VERSION ""

NS_ :

BS_:

BU_: XXX

BO_ 85 CID_RHFDFQ: 8 XXX
 SG_ sig_znnjpg : 40|1@1+ (1,0) [0|1] "" XXX
 SG_ sig_tseiik : 56|8@1+ (1,0) [0|255] "" XXX

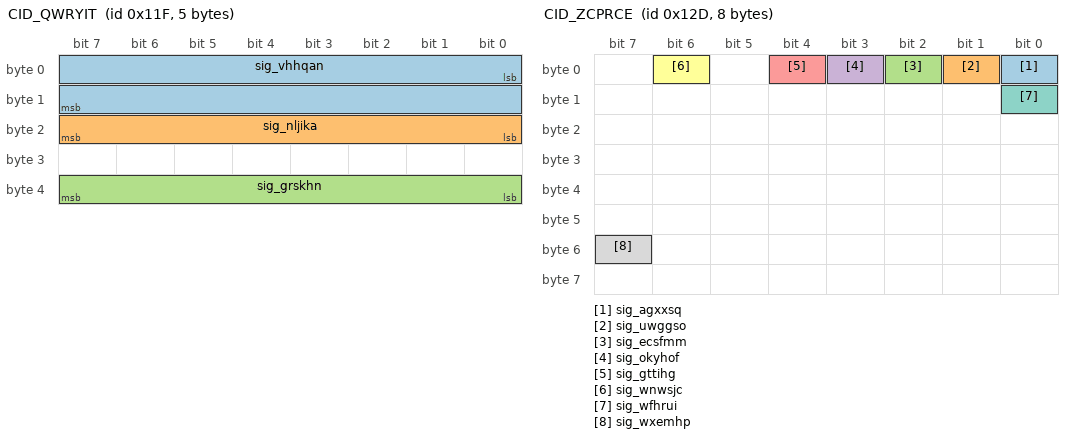
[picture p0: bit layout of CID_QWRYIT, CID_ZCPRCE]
BO_ 287 CID_QWRYIT: 5 XXX
 SG_ sig_vhhqan : 0|16@1- (0.1,0) [-450|450] "" XXX
 SG_ sig_nljika : 16|8@1+ (4,0) [0|1020] "" XXX
 SG_ sig_grskhn : 32|8@1+ (1,0) [0|255] "" XXX

BO_ 289 CID_XDWTUO: 8 XXX
 SG_ sig_wvsqzv : 0|12@1+ (1,0) [0|255] "" XXX

BO_ 301 CID_ZCPRCE: 8 XXX
 SG_ sig_agxxsq : 0|1@0+ (1,0) [0|1] "" XXX
 SG_ sig_uwggso : 1|1@0+ (1,0) [0|1] "" XXX
 SG_ sig_ecsfmm : 2|1@0+ (1,0) [0|1] "" XXX
 SG_ sig_okyhof : 3|1@0+ (1,0) [0|1] "" XXX
 SG_ sig_gttihg : 4|1@0+ (1,0) [0|1] "" XXX
 SG_ sig_wnwsjc : 6|1@0+ (1,0) [0|1] "" XXX
 SG_ sig_wfhrui : 8|1@0+ (1,0) [0|1] "" XXX
 SG_ sig_wxemhp : 55|1@0+ (1,0) [0|1] "" XXX

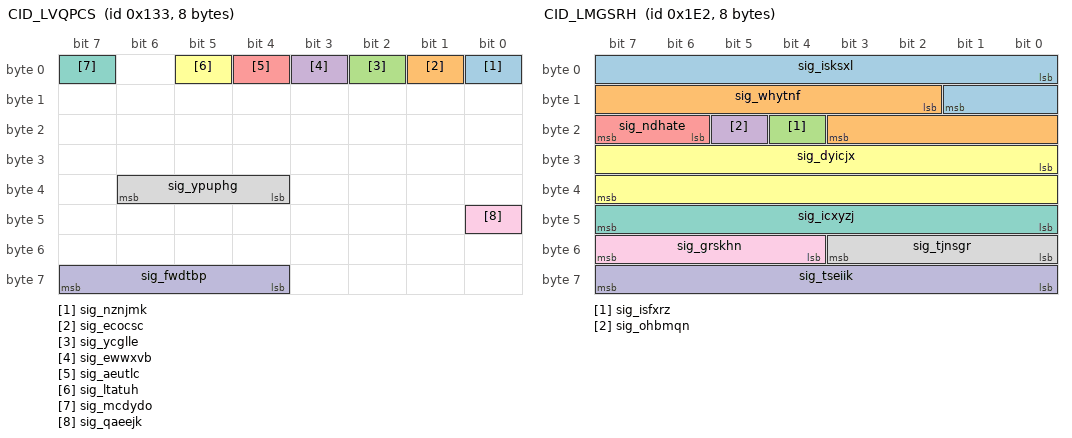
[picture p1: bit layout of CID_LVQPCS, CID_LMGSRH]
BO_ 307 CID_LVQPCS: 8 XXX
 SG_ sig_nznjmk : 0|1@0+ (1,0) [0|1] "" XXX
 SG_ sig_ecocsc : 1|1@1+ (1,0) [0|1] "" XXX
 SG_ sig_ycglle : 2|1@1+ (1,0) [0|1] "" XXX
 SG_ sig_ewwxvb : 3|1@1+ (1,0) [0|1] "" XXX
 SG_ sig_aeutlc : 4|1@0+ (1,0) [0|1] "" XXX
 SG_ sig_ltatuh : 5|1@0+ (1,0) [0|1] "" XXX
 SG_ sig_mcdydo : 7|1@0+ (1,0) [0|1] "" XXX
 SG_ sig_ypuphg : 36|3@1+ (1,0) [0|7] "" XXX
 SG_ sig_qaeejk : 40|1@0+ (1,0) [0|1] "" XXX
 SG_ sig_fwdtbp : 63|4@0+ (1,0) [0|15] "" XXX

BO_ 482 CID_LMGSRH: 8 XXX
 SG_ sig_isksxl : 0|10@1- (0.01,0) [0|5] "" XXX
 SG_ sig_whytnf : 10|10@1- (0.01,0) [-5|0] "" XXX
 SG_ sig_isfxrz : 20|1@0+ (1,0) [0|1] "" XXX
 SG_ sig_ohbmqn : 21|1@0+ (1,0) [0|1] "" XXX
 SG_ sig_ndhate : 22|2@1+ (1,0) [0|1] "" XXX
 SG_ sig_dyicjx : 24|16@1- (0.1,0) [-780|779.9] "" XXX
 SG_ sig_icxyzj : 47|8@0+ (1,0) [0|255] "" XXX
 SG_ sig_tjnsgr : 48|4@1+ (1,0) [0|15] "" XXX
 SG_ sig_grskhn : 52|4@1+ (1,0) [0|15] "" XXX
 SG_ sig_tseiik : 56|8@1+ (1,0) [0|255] "" XXX

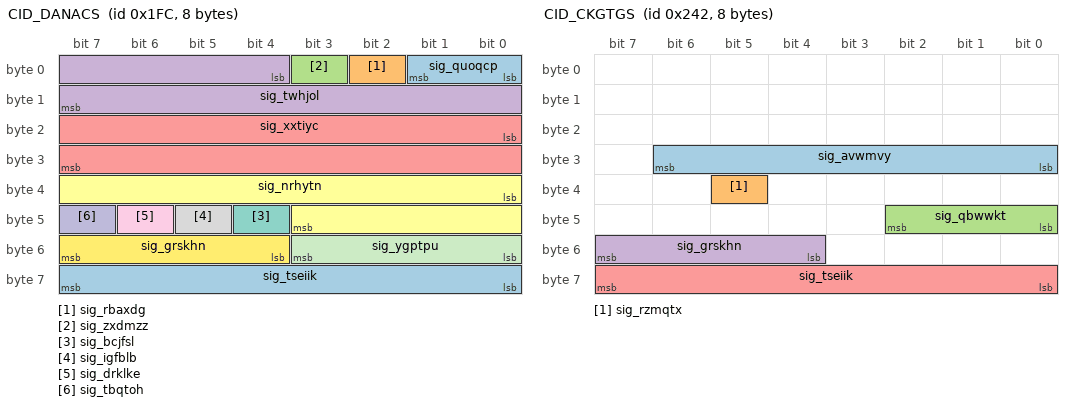
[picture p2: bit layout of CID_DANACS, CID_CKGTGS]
BO_ 508 CID_DANACS: 8 XXX
 SG_ sig_quoqcp : 0|2@1+ (1,0) [0|1] "" XXX
 SG_ sig_rbaxdg : 2|1@1+ (1,0) [0|1] "" XXX
 SG_ sig_zxdmzz : 3|1@0+ (1,0) [0|1] "" XXX
 SG_ sig_twhjol : 4|12@1- (1,0) [-2048|2047] "" XXX
 SG_ sig_xxtiyc : 16|16@1- (0.1,0) [-780|779.9] "Deg" XXX
 SG_ sig_nrhytn : 32|12@1- (0.01,0) [0|63] "" XXX
 SG_ sig_bcjfsl : 44|1@0+ (1,0) [0|1] "" XXX
 SG_ sig_igfblb : 45|1@1+ (1,0) [0|255] "" XXX
 SG_ sig_drklke : 46|1@1+ (1,0) [0|1] "" XXX
 SG_ sig_tbqtoh : 47|1@0+ (1,0) [0|3] "" XXX
 SG_ sig_ygptpu : 48|4@1+ (1,0) [0|15] "" XXX
 SG_ sig_grskhn : 52|4@1+ (1,0) [0|15] "" XXX
 SG_ sig_tseiik : 56|8@1+ (1,0) [0|255] "" XXX

BO_ 578 CID_CKGTGS: 8 XXX
 SG_ sig_avwmvy : 30|7@0+ (1,0) [0|127] "" XXX
 SG_ sig_rzmqtx : 37|1@0+ (1,0) [0|1] "" XXX
 SG_ sig_qbwwkt : 40|3@1+ (1,0) [0|7] "" XXX
 SG_ sig_grskhn : 55|4@0+ (1,0) [0|15] "" XXX
 SG_ sig_tseiik : 56|8@1+ (1,0) [0|255] "" XXX

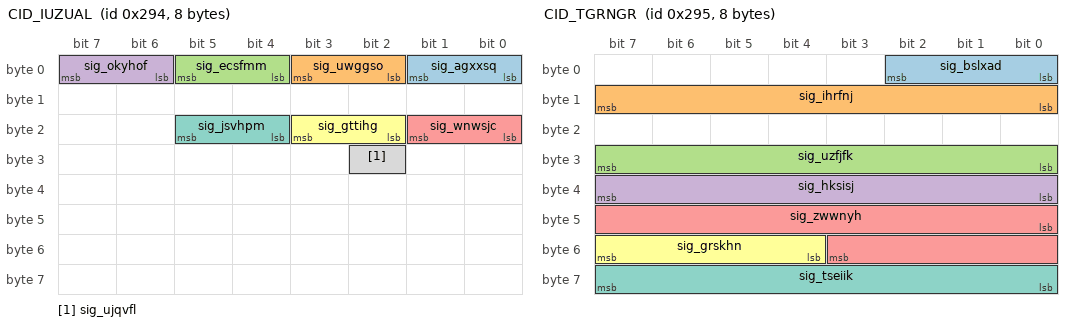
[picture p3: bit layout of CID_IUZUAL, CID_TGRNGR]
BO_ 660 CID_IUZUAL: 8 XXX
 SG_ sig_agxxsq : 1|2@0+ (1,0) [0|3] "" XXX
 SG_ sig_uwggso : 3|2@0+ (1,0) [0|3] "" XXX
 SG_ sig_ecsfmm : 5|2@0+ (1,0) [0|3] "" XXX
 SG_ sig_okyhof : 7|2@0+ (1,0) [0|3] "" XXX
 SG_ sig_wnwsjc : 17|2@0+ (1,0) [0|3] "" XXX
 SG_ sig_gttihg : 19|2@0+ (1,0) [0|3] "" XXX
 SG_ sig_jsvhpm : 21|2@0+ (1,0) [0|3] "" XXX
 SG_ sig_ujqvfl : 26|1@0+ (1,0) [0|1] "" XXX

BO_ 661 CID_TGRNGR: 8 XXX
 SG_ sig_bslxad : 2|3@0+ (1,0) [0|7] "" XXX
 SG_ sig_ihrfnj : 15|8@0+ (1,0) [0|255] "" XXX
 SG_ sig_uzfjfk : 31|8@0+ (1,0) [0|255] "" XXX
 SG_ sig_hksisj : 32|8@1+ (1,0) [0|255] "" XXX
 SG_ sig_zwwnyh : 40|12@1+ (1,0) [0|255] "" XXX
 SG_ sig_grskhn : 52|4@1+ (1,0) [0|15] "" XXX
 SG_ sig_tseiik : 63|8@0+ (1,0) [0|255] "" XXX

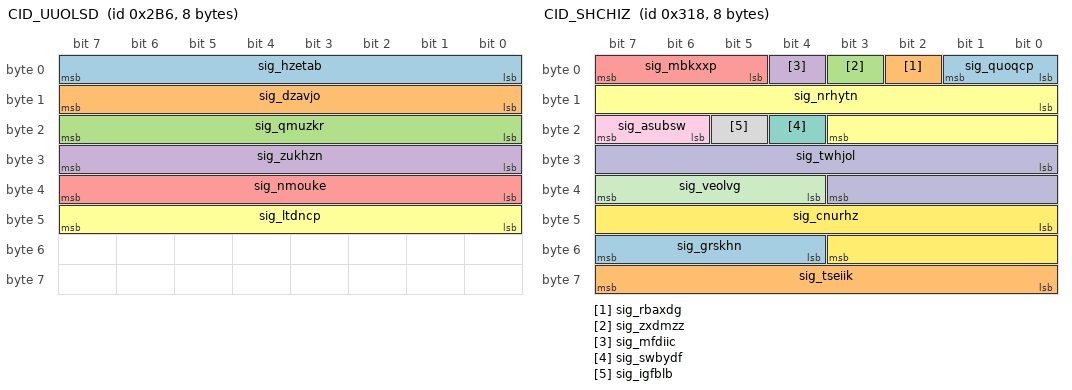
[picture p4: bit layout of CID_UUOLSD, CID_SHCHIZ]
BO_ 694 CID_UUOLSD: 8 XXX
 SG_ sig_hzetab : 7|8@0+ (1,0) [0|255] "" XXX
 SG_ sig_dzavjo : 15|8@0+ (1,0) [0|255] "" XXX
 SG_ sig_qmuzkr : 23|8@0+ (1,0) [0|255] "" XXX
 SG_ sig_zukhzn : 31|8@0+ (1,0) [0|255] "" XXX
 SG_ sig_nmouke : 39|8@0+ (1,0) [0|255] "" XXX
 SG_ sig_ltdncp : 47|8@0+ (1,0) [0|255] "" XXX

BO_ 790 CID_JWLQIV: 8 XXX
 SG_ sig_wcencc : 3|4@0+ (1,0) [0|1] "" XXX
 SG_ sig_gbtkds : 4|2@1+ (1,0) [0|3] "" XXX
 SG_ sig_mngrcc : 6|2@1+ (1,0) [0|3] "" XXX
 SG_ sig_escnyb : 8|2@1+ (1,0) [0|3] "" XXX
 SG_ sig_bfkyhb : 10|1@1+ (1,0) [0|1] "" XXX
 SG_ sig_whcnzq : 11|4@1+ (1,0) [0|1] "" XXX
 SG_ sig_jbddyf : 15|1@0+ (1,0) [0|1] "" XXX
 SG_ sig_dyicjx : 16|11@1- (1,0) [-1024|1023] "" XXX
 SG_ sig_isfxrz : 27|1@1+ (1,0) [0|1] "" XXX
 SG_ sig_ohbmqn : 28|1@1+ (1,0) [0|3] "" XXX
 SG_ sig_urutwc : 29|1@0+ (1,0) [0|1] "" XXX
 SG_ sig_sravbp : 30|1@0+ (1,0) [0|1] "" XXX
 SG_ sig_xznxlr : 31|1@0+ (1,0) [0|1] "" XXX
 SG_ sig_kikiai : 32|2@1+ (1,0) [0|3] "" XXX
 SG_ sig_njoawa : 34|2@1+ (1,0) [0|3] "" XXX
 SG_ sig_tvrrfl : 36|4@1+ (1,0) [0|3] "" XXX
 SG_ sig_pifalm : 40|8@1+ (5,-5) [-5|1270] "" XXX
 SG_ sig_rbadqu : 49|2@0+ (1,0) [0|3] "" XXX
 SG_ sig_kjogew : 51|2@0+ (1,0) [0|3] "" XXX
 SG_ sig_grskhn : 52|4@1+ (1,0) [0|15] "" XXX
 SG_ sig_tseiik : 56|8@1+ (1,0) [0|15] "" XXX

BO_ 792 CID_SHCHIZ: 8 XXX
 SG_ sig_quoqcp : 0|2@1+ (1,0) [0|1] "" XXX
 SG_ sig_rbaxdg : 2|1@1+ (1,0) [0|1] "" XXX
 SG_ sig_zxdmzz : 3|1@1+ (1,0) [0|1] "" XXX
 SG_ sig_mfdiic : 4|1@1+ (1,0) [0|1] "" XXX
 SG_ sig_mbkxxp : 5|3@1+ (1,0) [0|1] "" XXX
 SG_ sig_nrhytn : 8|12@1- (1,0) [-2048|2047] "" XXX
 SG_ sig_swbydf : 20|1@1+ (1,0) [0|1] "" XXX
 SG_ sig_igfblb : 21|1@1+ (1,0) [0|1] "" XXX
 SG_ sig_asubsw : 22|2@1+ (1,0) [0|15] "" XXX
 SG_ sig_twhjol : 24|12@1- (1,0) [-2048|2047] "" XXX
 SG_ sig_veolvg : 36|4@1+ (1,0) [0|15] "" XXX
 SG_ sig_cnurhz : 40|12@1+ (1,0) [0|4095] "" XXX
 SG_ sig_grskhn : 52|4@1+ (1,0) [0|15] "" XXX
 SG_ sig_tseiik : 56|8@1+ (1,0) [0|255] "" XXX

BO_ 813 CID_TNAPHC: 8 XXX
 SG_ sig_nvflcf : 0|9@1+ (0.5,0) [0|255.5] "" XXX
 SG_ sig_aijphs : 9|1@1+ (1,0) [0|1] "" XXX
 SG_ sig_cakkvc : 10|3@1+ (1,0) [0|7] "" XXX
 SG_ sig_sthjfq : 13|3@1+ (1,0) [0|7] "" XXX
 SG_ sig_nvhvmy : 16|1@1+ (1,0) [0|1] "" XXX
 SG_ sig_vmadpy : 17|1@1+ (1,0) [0|1] "" XXX
 SG_ sig_zxdmzz : 18|1@1+ (1,0) [0|1] "" XXX
 SG_ sig_nmroux : 19|3@1+ (1,0) [0|1] "" XXX
 SG_ sig_mdghmj : 22|1@0+ (1,0) [0|1] "" XXX
 SG_ sig_foscgl : 23|1@0+ (1,0) [0|1] "" XXX
 SG_ sig_escnyb : 24|1@1+ (1,0) [0|1] "" XXX
 SG_ sig_mnsrvi : 25|7@1+ (1,0) [0|127] "" XXX
 SG_ sig_mrujsp : 32|4@1+ (1,0) [0|15] "" XXX
 SG_ sig_shipue : 36|12@1+ (1,0) [0|4095] "" XXX
 SG_ sig_grskhn : 48|4@1+ (1,0) [0|15] "" XXX
 SG_ sig_aszoli : 55|4@0+ (1,0) [0|15] "" XXX
 SG_ sig_tseiik : 56|8@1+ (1,0) [0|255] "" XXX

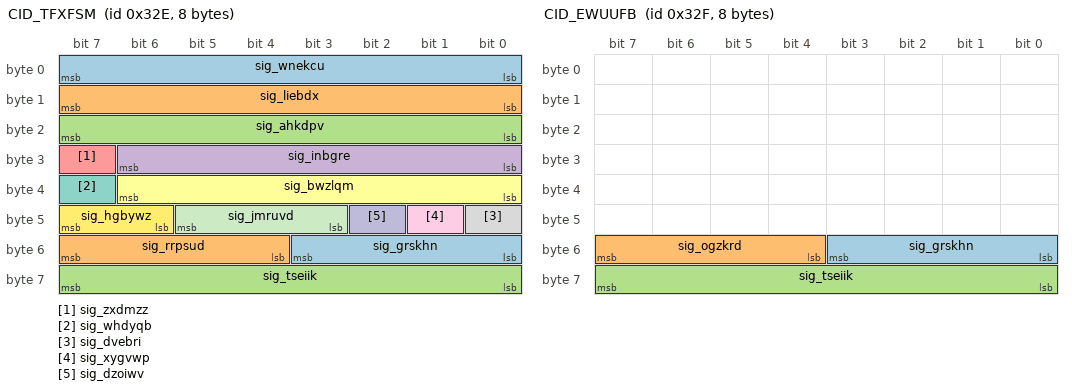
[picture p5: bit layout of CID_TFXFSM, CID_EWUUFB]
BO_ 814 CID_TFXFSM: 8 XXX
 SG_ sig_wnekcu : 0|8@1+ (0.05,-5) [-100|155] "" XXX
 SG_ sig_liebdx : 8|8@1+ (0.05,-5) [0|1.26] "" XXX
 SG_ sig_ahkdpv : 16|8@1+ (0.05,-5) [0|1.26] "" XXX
 SG_ sig_inbgre : 24|7@1+ (0.2,0) [0|12.7] "" XXX
 SG_ sig_zxdmzz : 31|1@0+ (1,0) [0|1] "" XXX
 SG_ sig_bwzlqm : 32|7@1+ (0.2,-16) [0|12.7] "" XXX
 SG_ sig_whdyqb : 39|1@0+ (1,0) [0|1] "" XXX
 SG_ sig_dvebri : 40|1@0+ (1,0) [0|1] "" XXX
 SG_ sig_xygvwp : 41|1@0+ (1,0) [0|1] "" XXX
 SG_ sig_dzoiwv : 42|1@1+ (1,0) [0|3] "" XXX
 SG_ sig_jmruvd : 45|3@0+ (1,0) [0|1] "" XXX
 SG_ sig_hgbywz : 46|2@1+ (1,0) [0|3] "" XXX
 SG_ sig_grskhn : 48|4@1+ (1,0) [0|15] "" XXX
 SG_ sig_rrpsud : 55|4@0+ (1,0) [0|15] "" XXX
 SG_ sig_tseiik : 56|8@1+ (1,0) [0|255] "" XXX

BO_ 815 CID_EWUUFB: 8 XXX
 SG_ sig_grskhn : 48|4@1+ (1,0) [0|15] "" XXX
 SG_ sig_ogzkrd : 55|4@0+ (1,0) [0|15] "" XXX
 SG_ sig_tseiik : 56|8@1+ (1,0) [0|255] "" XXX

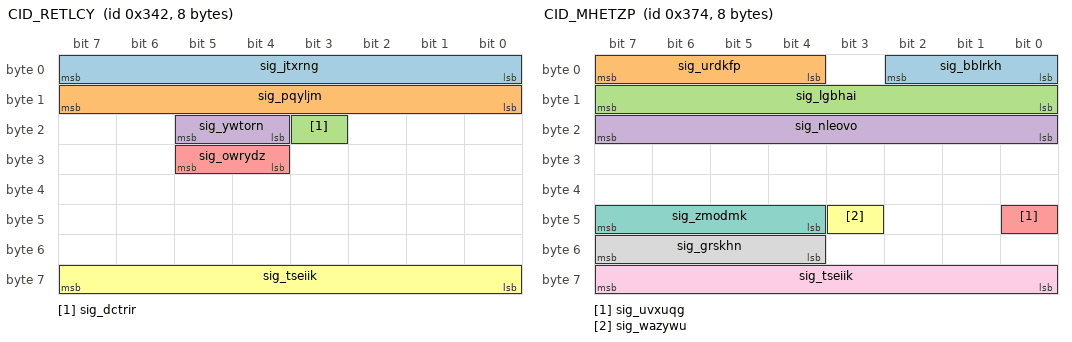
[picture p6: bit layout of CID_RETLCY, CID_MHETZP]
BO_ 834 CID_RETLCY: 8 XXX
 SG_ sig_jtxrng : 0|8@1+ (0.01,0) [0|2.55] "" XXX
 SG_ sig_pqyljm : 8|8@1+ (0.01,0) [0|2.55] "" XXX
 SG_ sig_dctrir : 19|1@1+ (1,0) [0|1] "" XXX
 SG_ sig_ywtorn : 20|2@1+ (1,0) [0|255] "" XXX
 SG_ sig_owrydz : 28|2@1+ (1,0) [0|1] "" XXX
 SG_ sig_tseiik : 56|8@1+ (1,0) [0|255] "" XXX

 BO_ 884 CID_MHETZP: 8 MRR
 SG_ sig_bblrkh : 2|3@0+ (1,0) [0|3] "" MRR
 SG_ sig_urdkfp : 7|4@0+ (1,0) [0|15] "" MRR
 SG_ sig_lgbhai : 15|8@0+ (0.1,-12) [0|255] "" MRR
 SG_ sig_nleovo : 23|8@0+ (1,-100) [0|255] "" MRR
 SG_ sig_uvxuqg : 40|1@0+ (1,0) [0|3] "" MRR
 SG_ sig_wazywu : 43|1@0+ (1,0) [0|1] "" XXX
 SG_ sig_zmodmk : 44|4@1+ (1,0) [0|15] "" XXX
 SG_ sig_grskhn : 52|4@1+ (1,0) [0|15] "" MRR
 SG_ sig_tseiik : 56|8@1+ (1,0) [0|255] "" MRR

BO_ 944 CID_HQDJRV: 8 XXX
 SG_ sig_hphfld : 1|2@0+ (1,0) [0|3] "" XXX
 SG_ sig_ehgzet : 2|1@0+ (1,0) [0|1] "" XXX
 SG_ sig_pbttzy : 4|2@0+ (1,0) [0|3] "" XXX
 SG_ sig_hqtlpm : 5|1@0+ (1,0) [0|1] "" XXX
 SG_ sig_dxrsso : 6|1@0+ (1,0) [0|1] "" XXX
 SG_ sig_bxando : 7|1@0+ (1,0) [0|1] "" XXX
 SG_ sig_jvqgdz : 8|1@0+ (1,0) [0|1] "" XXX
 SG_ sig_majstm : 11|3@0+ (1,0) [0|7] "" XXX
 SG_ sig_ptwmvb : 12|1@0+ (1,0) [0|1] "" XXX
 SG_ sig_giawgq : 14|2@0+ (1,0) [0|3] "" XXX
 SG_ sig_fhlhlz : 15|1@0+ (1,0) [0|1] "" XXX
 SG_ sig_doduql : 16|1@0+ (1,0) [0|1] "" XXX
 SG_ sig_qoobtp : 18|2@0+ (1,0) [0|3] "" XXX
 SG_ sig_pgihla : 19|1@0+ (1,0) [0|1] "" XXX
 SG_ sig_mdabiq : 23|4@0+ (1,0) [0|15] "" XXX
 SG_ sig_xnozjp : 24|28@1+ (1,0) [0|268435455] "" XXX
 SG_ sig_grskhn : 52|4@1+ (1,0) [0|15] "" XXX
 SG_ sig_tseiik : 56|8@1+ (1,0) [0|255] "" XXX

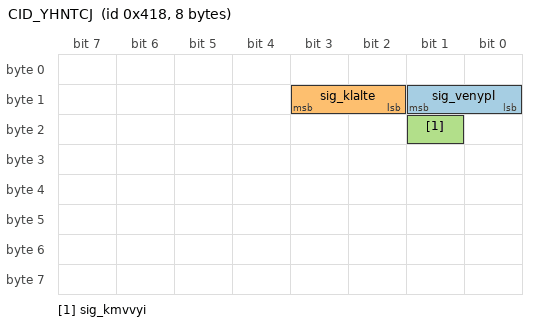
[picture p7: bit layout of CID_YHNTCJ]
BO_ 1048 CID_YHNTCJ: 8 XXX
 SG_ sig_venypl : 9|2@0+ (1,0) [0|1] "" XXX
 SG_ sig_klalte : 11|2@0+ (1,0) [0|1] "" XXX
 SG_ sig_kmvvyi : 17|1@0+ (1,0) [0|1] "" XXX

VAL_ 578 sig_qbwwkt 4 "D" 2 "R" 3 "N" 1 "P";
VAL_ 790 sig_wcencc 11 "AutoFullBeamActive" 2 "AutoFullBeamInactive";
VAL_ 790 sig_gbtkds 0 "GRAY" 1 "GREEN" 2 "YELLOW" 3 "RED";
VAL_ 790 sig_mngrcc 3 "ALARM_AND_LKA" 2 "LKA" 1 "ALARM" 0 "DISABLE";
VAL_ 790 sig_njoawa 0 "GRAY" 1 "GREEN" 2 "YELLOW" 3 "RED";
VAL_ 790 sig_rbadqu 0 "VIBRATION" 1 "AUDIO" 2 "AUDIO_AND_VIBRATION";
VAL_ 792 sig_quoqcp 0 "NotReady" 1 "Ready" 2 "Active" 3 "TemporaryFail";
VAL_ 813 sig_cakkvc 4 "4BAR" 3 "3BAR" 2 "2BAR" 1 "1BAR";
VAL_ 813 sig_nmroux 0 "OFF" 2 "ACC_ON" 3 "ACC_ACTIVE" 5 "FORCE_ACCEL" 7 "ERROR";
VAL_ 813 sig_mnsrvi 36 "ACC_ERROR" 22 "OVERRIDE" 12 "ENGAGE" 8 "DISENGAGE" 20 "ACC_ON" 32 "ACC_OFF" 48 "CHECK_GEAR_D" 16 "FORCE_ACCEL" 0 "NONE";
VAL_ 814 sig_jmruvd 0 "Off" 1 "Passive" 2 "StandBy" 3 "ActiveControl" 4 "BrakeOnly" 5 "Override" 6 "Standstill" 7 "Failure";
VAL_ 814 sig_hgbywz 0 "Softoff" 1 "Fastoff" 2 "Immediateoff" 3 "Initial";
VAL_ 834 sig_ywtorn 2 "SPORT" 1 "ECO" 0 "SNOW";
VAL_ 834 sig_owrydz 3 "HEV" 2 "FORCE_EV" 1 "EV";
VAL_ 944 sig_pbttzy 0 "NOTPRESSED" 1 "DOWN_SETSPEED" 3 "UP_RESETSPEED";
